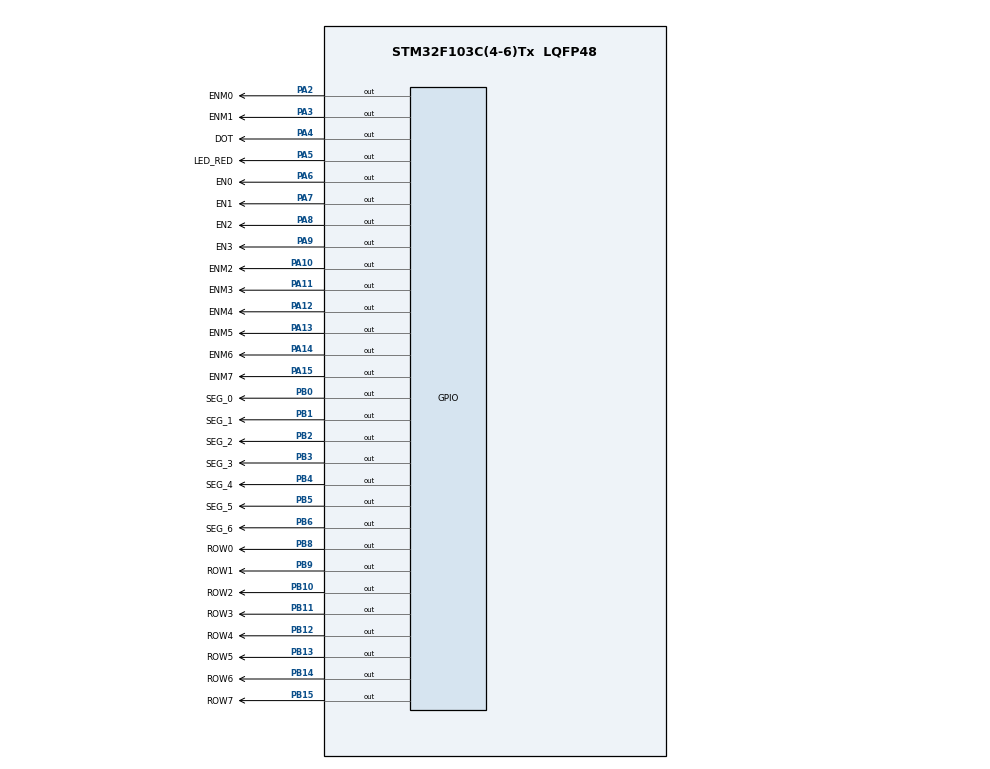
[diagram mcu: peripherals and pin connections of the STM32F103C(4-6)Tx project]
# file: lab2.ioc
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Mcu.Family=STM32F1
Mcu.Name=STM32F103C(4-6)Tx
Mcu.Package=LQFP48
NVIC.PriorityGroup=NVIC_PRIORITYGROUP_4
NVIC.TIM2_IRQn=true\:0\:0\:false\:false\:true\:true\:true\:true
PA10.GPIO_Label=ENM2
PA10.Signal=GPIO_Output
PA11.GPIO_Label=ENM3
PA11.Signal=GPIO_Output
PA12.GPIO_Label=ENM4
PA12.Signal=GPIO_Output
PA13.GPIO_Label=ENM5
PA13.Signal=GPIO_Output
PA14.GPIO_Label=ENM6
PA14.Signal=GPIO_Output
PA15.GPIO_Label=ENM7
PA15.Signal=GPIO_Output
PA2.GPIO_Label=ENM0
PA2.Signal=GPIO_Output
PA3.GPIO_Label=ENM1
PA3.Signal=GPIO_Output
PA4.GPIO_Label=DOT
PA4.Signal=GPIO_Output
PA5.GPIO_Label=LED_RED
PA5.Signal=GPIO_Output
PA6.GPIO_Label=EN0
PA6.Signal=GPIO_Output
PA7.GPIO_Label=EN1
PA7.Signal=GPIO_Output
PA8.GPIO_Label=EN2
PA8.Signal=GPIO_Output
PA9.GPIO_Label=EN3
PA9.Signal=GPIO_Output
PB0.GPIO_Label=SEG_0
PB0.Signal=GPIO_Output
PB1.GPIO_Label=SEG_1
PB1.Signal=GPIO_Output
PB10.GPIO_Label=ROW2
PB10.Signal=GPIO_Output
PB11.GPIO_Label=ROW3
PB11.Signal=GPIO_Output
PB12.GPIO_Label=ROW4
PB12.Signal=GPIO_Output
PB13.GPIO_Label=ROW5
PB13.Signal=GPIO_Output
PB14.GPIO_Label=ROW6
PB14.Signal=GPIO_Output
PB15.GPIO_Label=ROW7
PB15.Signal=GPIO_Output
PB2.GPIO_Label=SEG_2
PB2.Signal=GPIO_Output
PB3.GPIO_Label=SEG_3
PB3.Signal=GPIO_Output
PB4.GPIO_Label=SEG_4
PB4.Signal=GPIO_Output
PB5.GPIO_Label=SEG_5
PB5.Signal=GPIO_Output
PB6.GPIO_Label=SEG_6
PB6.Signal=GPIO_Output
PB8.GPIO_Label=ROW0
PB8.Signal=GPIO_Output
PB9.GPIO_Label=ROW1
PB9.Signal=GPIO_Output
ProjectManager.HeapSize=0x200
ProjectManager.StackSize=0x400
ProjectManager.TargetToolchain=STM32CubeIDE
RCC.APB1Freq_Value=8000000
RCC.APB2Freq_Value=8000000
TIM2.Period=9
TIM2.Prescaler=7999
VP_TIM2_VS_ClockSourceINT.Mode=Internal
board=custom

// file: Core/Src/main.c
/* USER CODE BEGIN Header */
/**
  ******************************************************************************
  * @file           : main.c
  * @brief          : Main program body
  ******************************************************************************
  * @attention
  *
  * Copyright (c) 2024 STMicroelectronics.
  * All rights reserved.
  *
  * This software is licensed under terms that can be found in the LICENSE file
  * in the root directory of this software component.
  * If no LICENSE file comes with this software, it is provided AS-IS.
  *
  ******************************************************************************
  */
/* USER CODE END Header */
#include "main.h"

/* USER CODE BEGIN Includes */
#include "led7.h"
#include "timer.h"
/* USER CODE END Includes */

TIM_HandleTypeDef htim2;

void SystemClock_Config(void);
static void MX_GPIO_Init(void);
static void MX_TIM2_Init(void);

#define NUM_TIMERS 10  // Number of timers you want to handle
#define TICK 10
int timer_flag[NUM_TIMERS];  // Timer flags for each timer
int timer_counter[NUM_TIMERS];  // Timer counters for each timer

int digit_index = 0;
const uint8_t digits[] = {1, 2, 3, 0};  // Digits to display in order
const uint16_t digit_pins[] = {GPIO_PIN_6, GPIO_PIN_7, GPIO_PIN_8, GPIO_PIN_9};  // PA6, PA7, PA8, PA9

#define MAX_LED 4
int led_buffer[MAX_LED];  // Example buffer with 4 digits to display
int index_led=0;

int hour = 15, minute = 8, second = 50;
int led_state=0;

void setTimer(int timer_id, int duration)
{
	if (timer_id >= 0 && timer_id < NUM_TIMERS)
	    {
	        timer_counter[timer_id] = duration / TICK;
	        timer_flag[timer_id] = 0;
	    }
}
void timerRun(void)
{
    for (int i = 0; i < NUM_TIMERS; i++)
    {
        if (timer_counter[i] >= 0)
        {
            timer_counter[i]--;  // Decrease the counter

            if (timer_counter[i] <= 0)
            {
                timer_flag[i] = 1;  // Timer expired
            }
        }
    }
}

void display_digit(uint8_t digit)
{
    display1(digit);
}
void update7SEG(int index) {
    switch (index) {
        case 0:
            display1(led_buffer[0]);
			HAL_GPIO_WritePin(EN0_GPIO_Port, EN0_Pin, 0);
			HAL_GPIO_WritePin(EN1_GPIO_Port, EN1_Pin, 1);
			HAL_GPIO_WritePin(EN2_GPIO_Port, EN2_Pin, 1);
			HAL_GPIO_WritePin(EN3_GPIO_Port, EN3_Pin, 1);
            break;
        case 1:
            display1(led_buffer[1]);
			HAL_GPIO_WritePin(EN0_GPIO_Port, EN0_Pin, 1);
			HAL_GPIO_WritePin(EN1_GPIO_Port, EN1_Pin, 0);
			HAL_GPIO_WritePin(EN2_GPIO_Port, EN2_Pin, 1);
			HAL_GPIO_WritePin(EN3_GPIO_Port, EN3_Pin, 1);
            break;
        case 2:
            display1(led_buffer[2]);
			HAL_GPIO_WritePin(EN0_GPIO_Port, EN0_Pin, 1);
			HAL_GPIO_WritePin(EN1_GPIO_Port, EN1_Pin, 1);
			HAL_GPIO_WritePin(EN2_GPIO_Port, EN2_Pin, 0);
			HAL_GPIO_WritePin(EN3_GPIO_Port, EN3_Pin, 1);
            break;
        case 3:
            display1(led_buffer[3]);
			HAL_GPIO_WritePin(EN0_GPIO_Port, EN0_Pin, 1);
			HAL_GPIO_WritePin(EN1_GPIO_Port, EN1_Pin, 1);
			HAL_GPIO_WritePin(EN2_GPIO_Port, EN2_Pin, 1);
			HAL_GPIO_WritePin(EN3_GPIO_Port, EN3_Pin, 0);
            break;
        default:
            break;
    }
}
void updateClockBuffer(void)
{
    uint8_t hour_tens = hour / 10;
    uint8_t hour_units = hour % 10;
    uint8_t minute_tens = minute / 10;
    uint8_t minute_units = minute % 10;

    led_buffer[0] = hour_tens;
    led_buffer[1] = hour_units;
    led_buffer[2] = minute_tens;
    led_buffer[3] = minute_units;
}
void update_timer(){
	if (timer_flag[0] == 1){
	          HAL_GPIO_TogglePin(DOT_GPIO_Port, DOT_Pin);
	          setTimer(0, 1000);
	      }

	      if (timer_flag[1] == 1){
				HAL_GPIO_WritePin(GPIOA, GPIO_PIN_6 | GPIO_PIN_7 | GPIO_PIN_8 | GPIO_PIN_9, 1);
				display_digit(led_buffer[index_led]);
				HAL_GPIO_WritePin(GPIOA, digit_pins[index_led], 0);
				update7SEG(index_led);
				index_led++;

				if (index_led >= 4) index_led = 0;
				setTimer(1,250);
			}
	      if (timer_flag[2] == 1){
	    	  second++;
	    	  	  if (second >= 60) {
	    	  		  second = 0;
	    	  		  minute++;
	    	  	  }
	    	  	  if( minute >= 60) {
	    	  		  minute = 0;
	    	  		  hour++;
	    	  	  }
	    	  	  if( hour >=24){
	    	  		  hour = 0;
	    	  	  }
	    	  	  updateClockBuffer();
	      	setTimer(2,1000);
	      }
}
void HAL_TIM_PeriodElapsedCallback (TIM_HandleTypeDef *htim)
{
	if (htim->Instance == TIM2){
	        timerRun();
	    }
	}

int main(void)
{

  /* MCU Configuration--------------------------------------------------------*/

  /* Reset of all peripherals, Initializes the Flash interface and the Systick. */
  HAL_Init();

  /* Configure the system clock */
  SystemClock_Config();

  /* USER CODE BEGIN SysInit */
  MX_GPIO_Init() ;
  MX_TIM2_Init() ;

  /* USER CODE END SysInit */

  /* Initialize all configured peripherals */
  MX_GPIO_Init();
  MX_TIM2_Init();
  /* USER CODE BEGIN 2 */
  HAL_TIM_Base_Start_IT(&htim2);
  /* USER CODE END 2 */

  /* Infinite loop */
  /* USER CODE BEGIN WHILE */

  setTimer(0,1000);
  setTimer(1,250);
  setTimer(2,1000);

  while (1)
  {
	  update_timer();
    /* USER CODE END WHILE */

  }
}

void SystemClock_Config(void)
{
  RCC_OscInitTypeDef RCC_OscInitStruct = {0};
  RCC_ClkInitTypeDef RCC_ClkInitStruct = {0};

  /** Initializes the RCC Oscillators according to the specified parameters
  * in the RCC_OscInitTypeDef structure.
  */
  RCC_OscInitStruct.OscillatorType = RCC_OSCILLATORTYPE_HSI;
  RCC_OscInitStruct.HSIState = RCC_HSI_ON;
  RCC_OscInitStruct.HSICalibrationValue = RCC_HSICALIBRATION_DEFAULT;
  RCC_OscInitStruct.PLL.PLLState = RCC_PLL_NONE;
  if (HAL_RCC_OscConfig(&RCC_OscInitStruct) != HAL_OK)
  {
    Error_Handler();
  }

  /** Initializes the CPU, AHB and APB buses clocks
  */
  RCC_ClkInitStruct.ClockType = RCC_CLOCKTYPE_HCLK|RCC_CLOCKTYPE_SYSCLK
                              |RCC_CLOCKTYPE_PCLK1|RCC_CLOCKTYPE_PCLK2;
  RCC_ClkInitStruct.SYSCLKSource = RCC_SYSCLKSOURCE_HSI;
  RCC_ClkInitStruct.AHBCLKDivider = RCC_SYSCLK_DIV1;
  RCC_ClkInitStruct.APB1CLKDivider = RCC_HCLK_DIV1;
  RCC_ClkInitStruct.APB2CLKDivider = RCC_HCLK_DIV1;

  if (HAL_RCC_ClockConfig(&RCC_ClkInitStruct, FLASH_LATENCY_0) != HAL_OK)
  {
    Error_Handler();
  }
}

static void MX_TIM2_Init(void)
{

  TIM_ClockConfigTypeDef sClockSourceConfig = {0};
  TIM_MasterConfigTypeDef sMasterConfig = {0};

  htim2.Instance = TIM2;
  htim2.Init.Prescaler = 7999;
  htim2.Init.CounterMode = TIM_COUNTERMODE_UP;
  htim2.Init.Period = 9;
  htim2.Init.ClockDivision = TIM_CLOCKDIVISION_DIV1;
  htim2.Init.AutoReloadPreload = TIM_AUTORELOAD_PRELOAD_DISABLE;
  if (HAL_TIM_Base_Init(&htim2) != HAL_OK)
  {
    Error_Handler();
  }
  sClockSourceConfig.ClockSource = TIM_CLOCKSOURCE_INTERNAL;
  if (HAL_TIM_ConfigClockSource(&htim2, &sClockSourceConfig) != HAL_OK)
  {
    Error_Handler();
  }
  sMasterConfig.MasterOutputTrigger = TIM_TRGO_RESET;
  sMasterConfig.MasterSlaveMode = TIM_MASTERSLAVEMODE_DISABLE;
  if (HAL_TIMEx_MasterConfigSynchronization(&htim2, &sMasterConfig) != HAL_OK)
  {
    Error_Handler();
  }

}

static void MX_GPIO_Init(void)
{
  GPIO_InitTypeDef GPIO_InitStruct = {0};

  /* GPIO Ports Clock Enable */
  __HAL_RCC_GPIOA_CLK_ENABLE();
  __HAL_RCC_GPIOB_CLK_ENABLE();

  /*Configure GPIO pin Output Level */
  HAL_GPIO_WritePin(GPIOA, DOT_Pin|LED_RED_Pin|EN0_Pin|EN1_Pin
                          |EN2_Pin|EN3_Pin, GPIO_PIN_RESET);

  /*Configure GPIO pin Output Level */
  HAL_GPIO_WritePin(GPIOB, SEG_0_Pin|SEG_1_Pin|SEG_2_Pin|SEG_3_Pin
                          |SEG_4_Pin|SEG_5_Pin|SEG_6_Pin, GPIO_PIN_RESET);

  /*Configure GPIO pins : DOT_Pin LED_RED_Pin EN0_Pin EN1_Pin
                           EN2_Pin EN3_Pin */
  GPIO_InitStruct.Pin = DOT_Pin|LED_RED_Pin|EN0_Pin|EN1_Pin
                          |EN2_Pin|EN3_Pin;
  GPIO_InitStruct.Mode = GPIO_MODE_OUTPUT_PP;
  GPIO_InitStruct.Pull = GPIO_NOPULL;
  GPIO_InitStruct.Speed = GPIO_SPEED_FREQ_LOW;
  HAL_GPIO_Init(GPIOA, &GPIO_InitStruct);

  /*Configure GPIO pins : SEG_0_Pin SEG_1_Pin SEG_2_Pin SEG_3_Pin
                           SEG_4_Pin SEG_5_Pin SEG_6_Pin */
  GPIO_InitStruct.Pin = SEG_0_Pin|SEG_1_Pin|SEG_2_Pin|SEG_3_Pin
                          |SEG_4_Pin|SEG_5_Pin|SEG_6_Pin;
  GPIO_InitStruct.Mode = GPIO_MODE_OUTPUT_PP;
  GPIO_InitStruct.Pull = GPIO_NOPULL;
  GPIO_InitStruct.Speed = GPIO_SPEED_FREQ_LOW;
  HAL_GPIO_Init(GPIOB, &GPIO_InitStruct);

}

void Error_Handler(void)
{
  __disable_irq();
  while (1)
  {
  }
}
